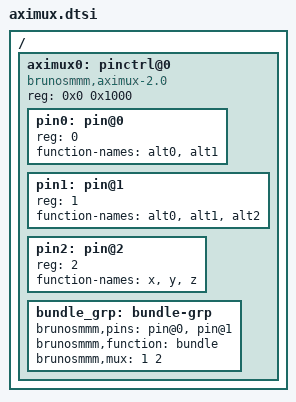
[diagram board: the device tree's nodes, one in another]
/ {
	aximux0: pinctrl@0 {
		compatible = "brunosmmm,aximux-2.0", "axi-mux-2.0";
		reg = <0x0 0x1000>;

		/* One child with `reg` per signal; names become 1-pin groups */
		pin0: pin@0 {
			reg = <0>;
			function-names = "alt0", "alt1";
		};

		pin1: pin@1 {
			reg = <1>;
			function-names = "alt0", "alt1", "alt2";
		};

		pin2: pin@2 {
			reg = <2>;
			function-names = "x", "y", "z";
		};

		/*
		 * Optional multi-pin group. Selecting function "bundle" on this
		 * group programs SRC for both pins from brunosmmm,mux.
		 */
		bundle_grp: bundle-grp {
			brunosmmm,pins = "pin@0", "pin@1";
			brunosmmm,function = "bundle";
			brunosmmm,mux = <1 2>;
		};
	};
};
